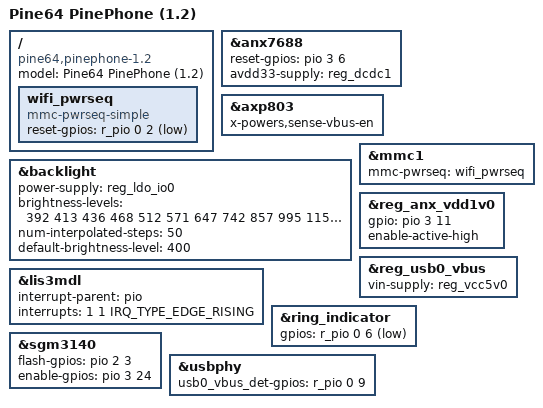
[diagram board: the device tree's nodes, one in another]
// SPDX-License-Identifier: (GPL-2.0+ OR MIT)
// Copyright (C) 2020 Ondrej Jirman <megous@megous.com>

/dts-v1/;

#include "sun50i-a64-pinephone.dtsi"

/ {
	model = "Pine64 PinePhone (1.2)";
	compatible = "pine64,pinephone-1.2", "allwinner,sun50i-a64";

	wifi_pwrseq: wifi_pwrseq {
		compatible = "mmc-pwrseq-simple";
		reset-gpios = <&r_pio 0 2 GPIO_ACTIVE_LOW>; /* PL2 */
	};
};

&anx7688 {
	reset-gpios = <&pio 3 6 GPIO_ACTIVE_HIGH>; /* PD6 */
	avdd33-supply = <&reg_dcdc1>;
};

&axp803 {
	x-powers,sense-vbus-en;
};

&backlight {
	power-supply = <&reg_ldo_io0>;
	/*
	 * PWM backlight circuit on this PinePhone revision was changed since 1.0,
	 * and the lowest PWM duty cycle that doesn't lead to backlight being off
	 * is around 10%. Duty cycle for the lowest brightness level also varries
	 * quite a bit between individual boards, so the lowest value here was
	 * chosen as a safe default.
	 */
	brightness-levels = <
		392  413  436  468
		512  571  647  742
		857  995  1159 1349
		1568 1819 2103 2423
		2779 3176 3614 4096>;
	num-interpolated-steps = <50>;
	default-brightness-level = <400>;
};

&lis3mdl {
	/*
	 * Board revision 1.2 fixed routing of the interrupt to DRDY pin,
	 * enable interrupts.
	 */
	interrupt-parent = <&pio>;
	interrupts = <1 1 IRQ_TYPE_EDGE_RISING>; /* PB1 */
};

&mmc1 {
	mmc-pwrseq = <&wifi_pwrseq>;
};

&reg_anx_vdd1v0 {
	gpio = <&pio 3 11 GPIO_ACTIVE_HIGH>; /* PD11 */
	enable-active-high;
};

&reg_usb0_vbus {
	/*
	 * ANX7688 will enable/disable USB-5V <-> DCIN switch by itself
	 * via VBUS_CTRL pin, so no GPIO is needed here.
	 */
	vin-supply = <&reg_vcc5v0>;
};

&ring_indicator {
	gpios = <&r_pio 0 6 GPIO_ACTIVE_LOW>; /* PL6 */
};

&sgm3140 {
	flash-gpios = <&pio 2 3 GPIO_ACTIVE_HIGH>; /* PC3 */
	enable-gpios = <&pio 3 24 GPIO_ACTIVE_HIGH>; /* PD24 */
};

&usbphy {
	usb0_vbus_det-gpios = <&r_pio 0 9 GPIO_ACTIVE_HIGH>; /* PL9 */
};
